VERSION ""

NS_ :

BS_:

BU_:

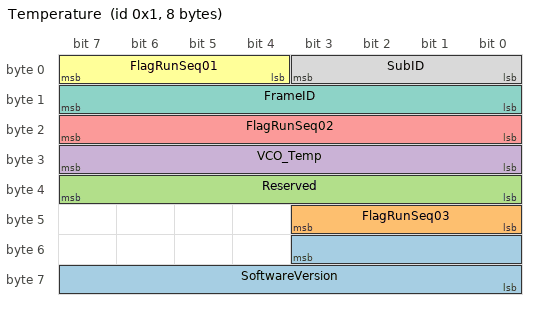
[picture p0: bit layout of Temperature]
BO_ 1 Temperature: 8 Vector__XXX
 SG_ SoftwareVersion : 51|12@0+ (1,0) [0|0] "" Vector__XXX
 SG_ FlagRunSeq03 : 43|4@0+ (1,0) [0|0] "" Vector__XXX
 SG_ Reserved : 39|8@0+ (1,0) [0|0] "" Vector__XXX
 SG_ VCO_Temp : 31|8@0+ (1,0) [0|0] "" Vector__XXX
 SG_ FlagRunSeq02 : 23|8@0+ (1,0) [0|0] "" Vector__XXX
 SG_ FlagRunSeq01 : 7|4@0+ (1,0) [0|0] "" Vector__XXX
 SG_ FrameID : 15|8@0+ (1,0) [0|0] "" Vector__XXX
 SG_ SubID : 3|4@0+ (1,0) [0|0] "" Vector__XXX

BA_DEF_  "BusType" STRING ;
BA_DEF_DEF_  "BusType" "CAN";
